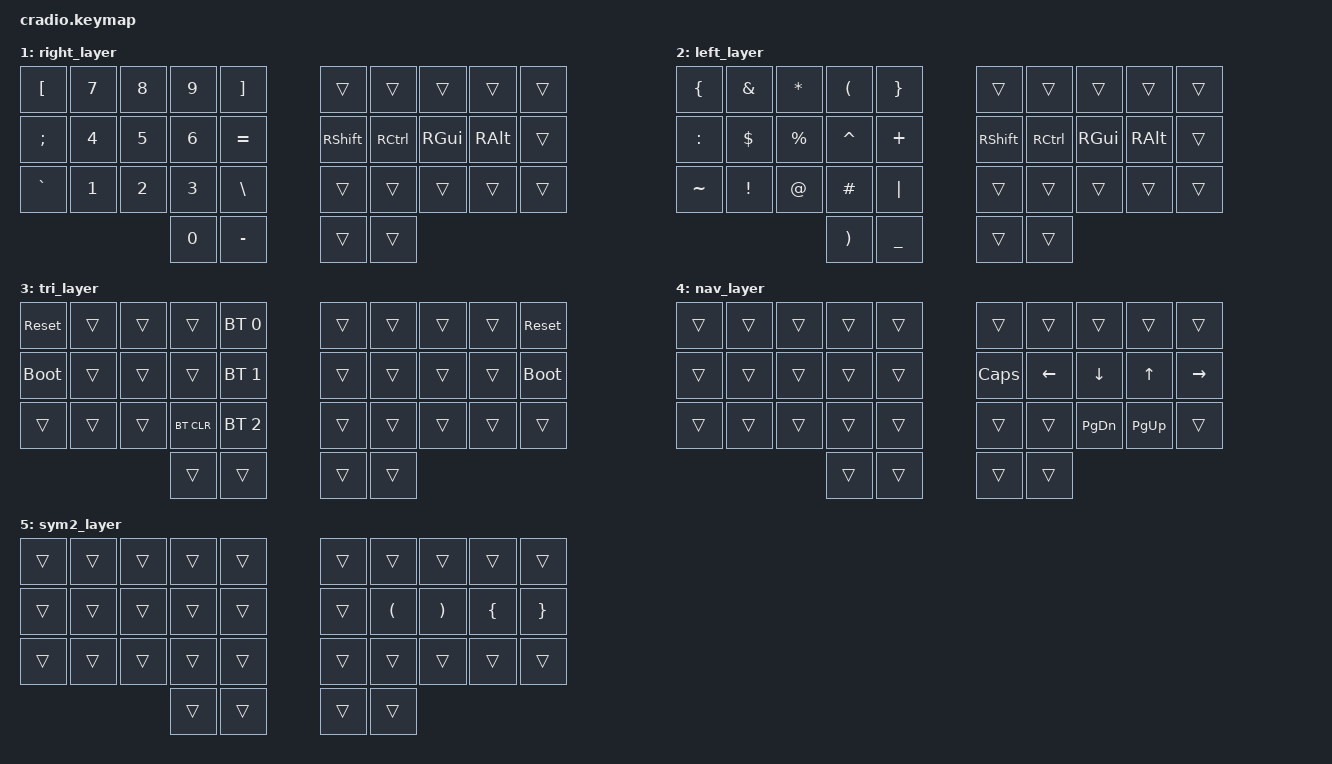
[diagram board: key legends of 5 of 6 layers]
// Copyright (c) 2022 The ZMK Contributors
// SPDX-License-Identifier: MIT

#include <behaviors.dtsi>
#include <dt-bindings/zmk/keys.h>
#include <dt-bindings/zmk/bt.h>

/ {
    combos {
        compatible = "zmk,combos";
        combo_esc {
            layers = <0>;
            timeout-ms = <50>;
            key-positions = <13 14>;
            bindings = <&kp ESC>;
        };
    };
};

// Home row mods macro
#define HRML(k1,k2,k3,k4) &ht LALT k1  &ht LGUI k2  &ht LCTRL k3  &ht LSHFT k4
#define HRMR(k1,k2,k3,k4) &ht RSHFT k1  &ht RCTRL k2  &ht RGUI k3  &ht RALT k4

/ {
    behaviors {
        ht: hold_tap {
            compatible = "zmk,behavior-hold-tap";
            #binding-cells = <2>;
            flavor = "tap-preferred";
            tapping-term-ms = <220>;
            quick-tap-ms = <150>;
            require-prior-idle-ms = <100>;
            bindings = <&kp>, <&kp>;
        };
    };

    conditional_layers {
        compatible = "zmk,conditional-layers";
        tri_layer {
            if-layers = <1 2>;
            then-layer = <3>;
        };
    };

    keymap {
        compatible = "zmk,keymap";
        default_layer {
            bindings = <
        //╭──────────┬──────────┬──────────┬──────────┬──────────╮   ╭──────────┬──────────┬──────────┬──────────┬──────────╮
        //│  Q       │  W       │  F       │  P       │  B       │   │  J       │  L       │  U       │  Y       │  ' "     │
            &kp Q      &kp W      &kp F      &kp P      &kp B          &kp J      &kp L      &kp U      &kp Y      &kp SQT
        //├──────────┼──────────┼──────────┼──────────┼──────────┤   ├──────────┼──────────┼──────────┼──────────┼──────────┤
        //│  A       │  R       │  S       │  T       │  G       │   │  M       │  N       │  E       │  I       │  O       │
            HRML(A,        R,         S,         T)     &kp G          &kp M      HRMR(N,        E,         I,        O)
        //├──────────┼──────────┼──────────┼──────────┼──────────┤   ├──────────┼──────────┼──────────┼──────────┼──────────┤
        //│  Z       │  X       │  C       │  D       │  V       │   │  K       │  H       │ , <      │ . >      │ / ?      │
            &kp Z      &kp X      &kp C      &kp D      &kp V          &kp K      &kp H      &kp COMMA  &kp DOT    &kp FSLH
        //╰──────────┴──────────┴──────────┼──────────┼──────────┤   ├──────────┼──────────┼──────────┴──────────┴──────────╯
                                            &lt 4 SPACE &lt 5 TAB    &lt 2 ENTER &lt 1 BSPC
        //                                 ╰──────────┴──────────╯   ╰──────────┴──────────╯
            >;
        };

        right_layer {
            bindings = <
        //╭──────────┬──────────┬──────────┬──────────┬──────────╮   ╭──────────┬──────────┬──────────┬──────────┬──────────╮
        //│ [        │  7       │  8       │  9       │ ]        │   │          │          │          │          │          │
            &kp LBKT   &kp N7     &kp N8     &kp N9     &kp RBKT       &trans     &trans     &trans     &trans     &trans
        //├──────────┼──────────┼──────────┼──────────┼──────────┤   ├──────────┼──────────┼──────────┼──────────┼──────────┤
        //│ ;        │  4       │  5       │  6       │ =        │   │          │          │          │          │          │
            &kp SEMI   &kp N4     &kp N5     &kp N6     &kp EQUAL      &kp RSHFT  &kp RCTRL  &kp RGUI   &kp RALT   &trans
        //├──────────┼──────────┼──────────┼──────────┼──────────┤   ├──────────┼──────────┼──────────┼──────────┼──────────┤
        //│ GRAVE    │  1       │  2       │  3       │ \        │   │          │          │          │          │          │
           &kp GRAVE   &kp N1     &kp N2     &kp N3     &kp BSLH       &trans     &trans     &trans     &trans     &trans
        //╰──────────┴──────────┴──────────┼──────────┼──────────┤   ├──────────┼──────────┼──────────┴──────────┴──────────╯
                                             &kp N0    &kp MINUS       &trans     &trans
        //                                 ╰──────────┴──────────╯   ╰──────────┴──────────╯
            >;
        };

        left_layer {
            bindings = <
        //╭──────────┬──────────┬──────────┬──────────┬──────────╮   ╭──────────┬──────────┬──────────┬──────────┬──────────╮
        //│  {       │  &       │  *       │  (       │  }       │   │          │          │          │          │          │
            &kp LBRC   &kp AMPS   &kp ASTRK  &kp LPAR   &kp RBRC       &trans     &trans     &trans     &trans     &trans
        //├──────────┼──────────┼──────────┼──────────┼──────────┤   ├──────────┼──────────┼──────────┼──────────┼──────────┤
        //│  :       │  $       │  %       │  ^       │  +       │   │          │          │          │          │          │
            &kp COLON  &kp DLLR   &kp PRCNT  &kp CARET  &kp PLUS       &kp RSHFT  &kp RCTRL  &kp RGUI   &kp RALT   &trans
        //├──────────┼──────────┼──────────┼──────────┼──────────┤   ├──────────┼──────────┼──────────┼──────────┼──────────┤
        //│  ~       │  !       │  @       │  #       │  |       │   │          │          │          │          │          │
            &kp TILDE  &kp EXCL   &kp AT     &kp HASH   &kp PIPE       &trans     &trans     &trans     &trans     &trans
        //╰──────────┴──────────┴──────────┼──────────┼──────────┤   ├──────────┼──────────┼──────────┴──────────┴──────────╯
                                             &kp RPAR  &kp UNDER       &trans     &trans
        //                                 ╰──────────┴──────────╯   ╰──────────┴──────────╯
            >;
        };

        tri_layer {
            bindings = <
        //╭──────────┬──────────┬──────────┬──────────┬──────────╮   ╭──────────┬──────────┬──────────┬──────────┬──────────╮
        //│ RESET    │          │          │          │PROFILE 0 │   │          │          │          │          │  RESET   │
           &sys_reset  &trans     &trans     &trans    &bt BT_SEL 0    &trans     &trans     &trans     &trans    &sys_reset
        //├──────────┼──────────┼──────────┼──────────┼──────────┤   ├──────────┼──────────┼──────────┼──────────┼──────────┤
        //│BOOTLOADER│          │          │          │PROFILE 1 │   │          │          │          │          │BOOTLOADER│
          &bootloader  &trans     &trans     &trans    &bt BT_SEL 1    &trans     &trans     &trans     &trans    &bootloader
        //├──────────┼──────────┼──────────┼──────────┼──────────┤   ├──────────┼──────────┼──────────┼──────────┼──────────┤
        //│          │          │          │ CLEAR BT │PROFILE 2 │   │          │          │          │          │          │
            &trans     &trans     &trans    &bt BT_CLR &bt BT_SEL 2    &trans     &trans     &trans     &trans     &trans
        //╰──────────┴──────────┴──────────┼──────────┼──────────┤   ├──────────┼──────────┼──────────┴──────────┴──────────╯
                                             &trans     &trans         &trans     &trans
        //                                 ╰──────────┴──────────╯   ╰──────────┴──────────╯
            >;
        };

        nav_layer {
            bindings = <
        //╭──────────┬──────────┬──────────┬──────────┬──────────╮   ╭──────────┬──────────┬──────────┬──────────┬──────────╮
        //│          │          │          │          │          │   │          │          │          │          │          │
            &trans     &trans     &trans     &trans     &trans         &trans     &trans     &trans     &trans     &trans
        //├──────────┼──────────┼──────────┼──────────┼──────────┤   ├──────────┼──────────┼──────────┼──────────┼──────────┤
        //│          │          │          │          │          │   │          │          │          │          │          │
            &trans     &trans     &trans     &trans     &trans         &kp CAPS   &kp LEFT   &kp DOWN   &kp UP     &kp RIGHT
        //├──────────┼──────────┼──────────┼──────────┼──────────┤   ├──────────┼──────────┼──────────┼──────────┼──────────┤
        //│          │          │          │          │          │   │          │          │          │          │          │
            &trans     &trans     &trans     &trans     &trans         &trans     &trans     &kp PG_DN  &kp PG_UP  &trans
        //╰──────────┴──────────┴──────────┼──────────┼──────────┤   ├──────────┼──────────┼──────────┴──────────┴──────────╯
                                             &trans     &trans         &trans     &trans
        //                                 ╰──────────┴──────────╯   ╰──────────┴──────────╯
            >;
        };

        sym2_layer {
            bindings = <
        //╭──────────┬──────────┬──────────┬──────────┬──────────╮   ╭──────────┬──────────┬──────────┬──────────┬──────────╮
        //│          │          │          │          │          │   │          │          │          │          │          │
            &trans     &trans     &trans     &trans     &trans         &trans     &trans     &trans     &trans     &trans
        //├──────────┼──────────┼──────────┼──────────┼──────────┤   ├──────────┼──────────┼──────────┼──────────┼──────────┤
        //│          │          │          │          │          │   │          │ (        │ )        │ {        │ }        │
            &trans     &trans     &trans     &trans     &trans         &trans     &kp LPAR   &kp RPAR   &kp LBRC   &kp RBRC
        //├──────────┼──────────┼──────────┼──────────┼──────────┤   ├──────────┼──────────┼──────────┼──────────┼──────────┤
        //│          │          │          │          │          │   │          │          │          │          │          │
            &trans     &trans     &trans     &trans     &trans         &trans     &trans     &trans     &trans     &trans
        //╰──────────┴──────────┴──────────┼──────────┼──────────┤   ├──────────┼──────────┼──────────┴──────────┴──────────╯
                                             &trans     &trans         &trans     &trans
        //                                 ╰──────────┴──────────╯   ╰──────────┴──────────╯
            >;
        };
    };
};
